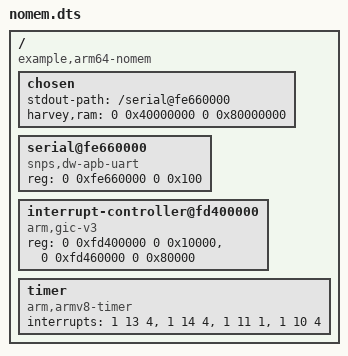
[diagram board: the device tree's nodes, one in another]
/dts-v1/;

/*
 * A board DTB with no /memory node, the way some firmware passes it.
 * /chosen/harvey,ram is the packer's fallback for exactly this case.
 */
/ {
	#address-cells = <2>;
	#size-cells = <2>;
	compatible = "example,arm64-nomem";

	chosen {
		stdout-path = "/serial@fe660000";
		harvey,ram = <0 0x40000000 0 0x80000000>;
	};

	serial@fe660000 {
		compatible = "snps,dw-apb-uart";
		reg = <0 0xfe660000 0 0x100>;
		status = "okay";
	};

	interrupt-controller@fd400000 {
		compatible = "arm,gic-v3";
		reg = <0 0xfd400000 0 0x10000>,
		      <0 0xfd460000 0 0x80000>;
	};

	timer {
		compatible = "arm,armv8-timer";
		interrupts = <1 13 4>, <1 14 4>, <1 11 1>, <1 10 4>;
	};
};
